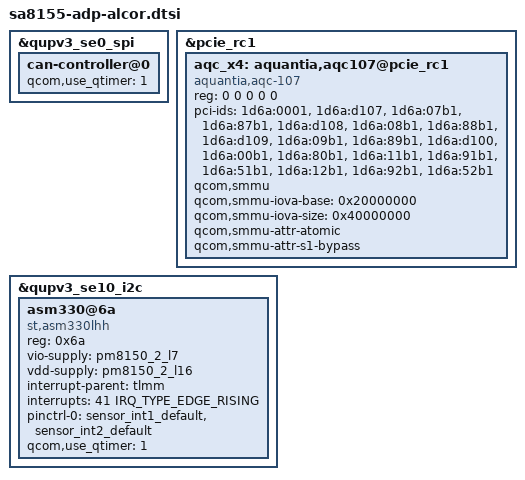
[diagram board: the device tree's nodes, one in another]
/* Copyright (c) 2019-2020, The Linux Foundation. All rights reserved.
 *
 * This program is free software; you can redistribute it and/or modify
 * it under the terms of the GNU General Public License version 2 and
 * only version 2 as published by the Free Software Foundation.
 *
 * This program is distributed in the hope that it will be useful,
 * but WITHOUT ANY WARRANTY; without even the implied warranty of
 * MERCHANTABILITY or FITNESS FOR A PARTICULAR PURPOSE.  See the
 * GNU General Public License for more details.
 */

#include "sa8155-adp-common.dtsi"
#include "sa8155-adp-alcor-display.dtsi"

&qupv3_se0_spi {
	can-controller@0 {
		qcom,use_qtimer = <1>; /* 0:Disable, 1:Enable */
	};
};

&pcie_rc1 {
	aqc_x4: aquantia,aqc107@pcie_rc1 {
		reg = <0 0 0 0 0>;
		compatible = "aquantia,aqc-107";
		pci-ids =
			"1d6a:0001",
			"1d6a:d107",
			"1d6a:07b1",
			"1d6a:87b1",
			"1d6a:d108",
			"1d6a:08b1",
			"1d6a:88b1",
			"1d6a:d109",
			"1d6a:09b1",
			"1d6a:89b1",
			"1d6a:d100",
			"1d6a:00b1",
			"1d6a:80b1",
			"1d6a:11b1",
			"1d6a:91b1",
			"1d6a:51b1",
			"1d6a:12b1",
			"1d6a:92b1",
			"1d6a:52b1";

		qcom,smmu;
		qcom,smmu-iova-base = /bits/ 64 <0x20000000>;
		qcom,smmu-iova-size = /bits/ 64 <0x40000000>;

		qcom,smmu-attr-atomic;
		qcom,smmu-attr-s1-bypass;
	};
};

&qupv3_se10_i2c {
	asm330@6a {
		compatible = "st,asm330lhh";
		reg = <0x6a>;
		vio-supply = <&pm8150_2_l7>;
		vdd-supply = <&pm8150_2_l16>;
		interrupt-parent = <&tlmm>;
		interrupts = <41 IRQ_TYPE_EDGE_RISING>;
		pinctrl-names = "default";
		pinctrl-0 = <&sensor_int1_default
			&sensor_int2_default>;
		qcom,use_qtimer = <1>; /* 0:Disable 1:Enable */
	};
};
